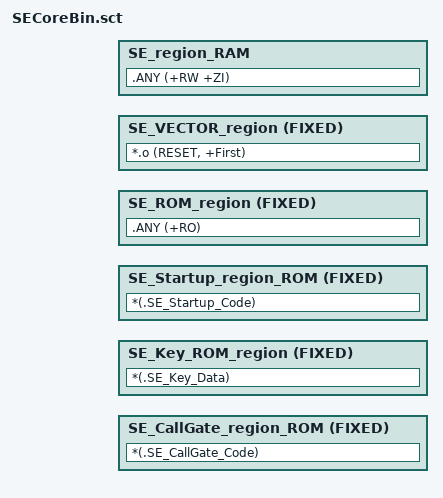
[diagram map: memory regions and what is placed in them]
#! armclang --target=arm-arm-none-eabi  -mcpu=cortex-m4 -E -xc
; *************************************************************
; *** Scatter-Loading Description File generated by uVision ***
; *************************************************************
#include "..\..\Linker_Common\MDK-ARM\mapping_sbsfu.h"
#include "..\..\Linker_Common\MDK-ARM\mapping_fwimg.h"


; *** regions needed by SE_CoreBin project ***
LR_SE_Entry_Secure_ROM_Region SE_CODE_REGION_ROM_START {
  SE_CallGate_region_ROM SE_CALLGATE_REGION_ROM_START FIXED SE_CALLGATE_REGION_ROM_SIZE {
  *(.SE_CallGate_Code)
  }
  SE_Key_ROM_region SE_KEY_REGION_ROM_START FIXED SE_KEY_REGION_ROM_SIZE {
  *(.SE_Key_Data)
  }
  SE_Startup_region_ROM SE_STARTUP_REGION_ROM_START FIXED  {
  *(.SE_Startup_Code)
  }
  SE_ROM_region SE_CODE_NOKEY_REGION_ROM_START FIXED SE_ROM_REGION_SIZE {
  .ANY (+RO)
  } 
  SE_VECTOR_region AlignExpr(ImageLimit(SE_ROM_region), VECTOR_SIZE) FIXED {
  *.o (RESET, +First)
  }
  SE_region_RAM SE_REGION_RAM_STACK_TOP SE_RAM_REGION_SIZE  {
  .ANY (+RW +ZI)
  }
}
  
